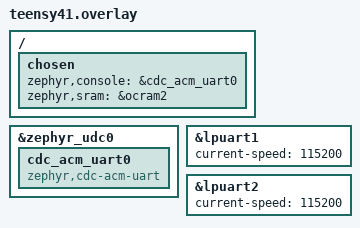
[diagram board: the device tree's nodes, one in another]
&zephyr_udc0 {
    cdc_acm_uart0: cdc_acm_uart0 {
        compatible = "zephyr,cdc-acm-uart";
    };
};

&lpuart1 {
	status = "okay";
	current-speed = < 115200 >;
};

&lpuart2 {
	status = "okay";
	current-speed = < 115200 >;
};

/ {
    chosen {
        zephyr,console = &cdc_acm_uart0;
        zephyr,sram = &ocram2;
    };
};
